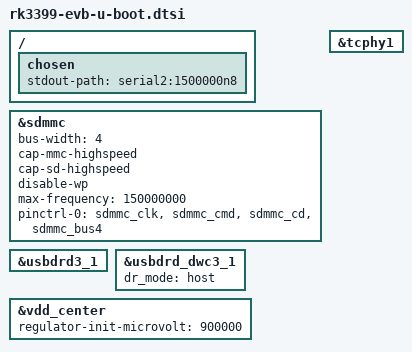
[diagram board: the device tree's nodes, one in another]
// SPDX-License-Identifier: GPL-2.0+
/*
 * Copyright (C) 2019 Jagan Teki <jagan@amarulasolutions.com>
 */

#include "rk3399-u-boot.dtsi"
#include "rk3399-sdram-lpddr3-4GB-1600.dtsi"

/ {
	chosen {
		stdout-path = "serial2:1500000n8";
	};
};

&sdmmc {
	bus-width = <4>;
	cap-mmc-highspeed;
	cap-sd-highspeed;
	disable-wp;
	max-frequency = <150000000>;
	pinctrl-names = "default";
	pinctrl-0 = <&sdmmc_clk &sdmmc_cmd &sdmmc_cd &sdmmc_bus4>;
	status = "okay";
};

&tcphy1 {
	status = "okay";
};

&usbdrd3_1 {
	status = "okay";
};

&usbdrd_dwc3_1 {
	dr_mode = "host";
	status = "okay";
};

&vdd_center {
	regulator-init-microvolt = <900000>;
};
